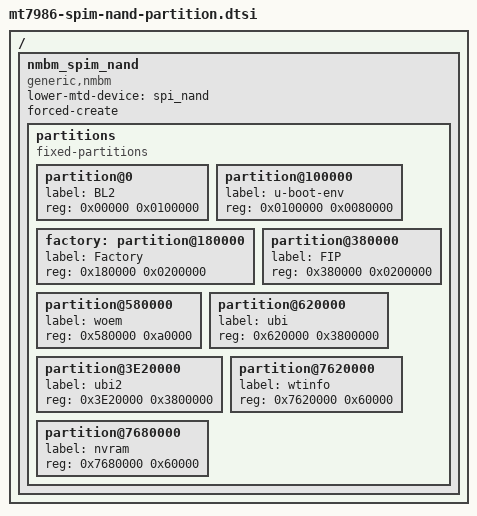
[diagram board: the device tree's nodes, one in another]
/ {
	nmbm_spim_nand {
		compatible = "generic,nmbm";

		#address-cells = <1>;
		#size-cells = <1>;

		lower-mtd-device = <&spi_nand>;
		forced-create;

		partitions {
			compatible = "fixed-partitions";
			#address-cells = <1>;
			#size-cells = <1>;

			partition@0 {
				label = "BL2";
				reg = <0x00000 0x0100000>;
			};

			partition@100000 {
				label = "u-boot-env";
				reg = <0x0100000 0x0080000>;
			};

			factory: partition@180000 {
				label = "Factory";
				reg = <0x180000 0x0200000>;
			};

			partition@380000 {
				label = "FIP";
				reg = <0x380000 0x0200000>;
			};

			partition@580000 {
				label = "woem";
				reg = <0x580000 0xa0000>;
			};

			partition@620000 {
				label = "ubi";
				reg = <0x620000 0x3800000>;
			};

			partition@3E20000 {
				label = "ubi2";
				reg = <0x3E20000 0x3800000>;
			};

			partition@7620000 {
				label = "wtinfo";
				reg = <0x7620000 0x60000>;
			};

			partition@7680000 {
				label = "nvram";
				reg = <0x7680000 0x60000>;
			};
		};
	};
};
